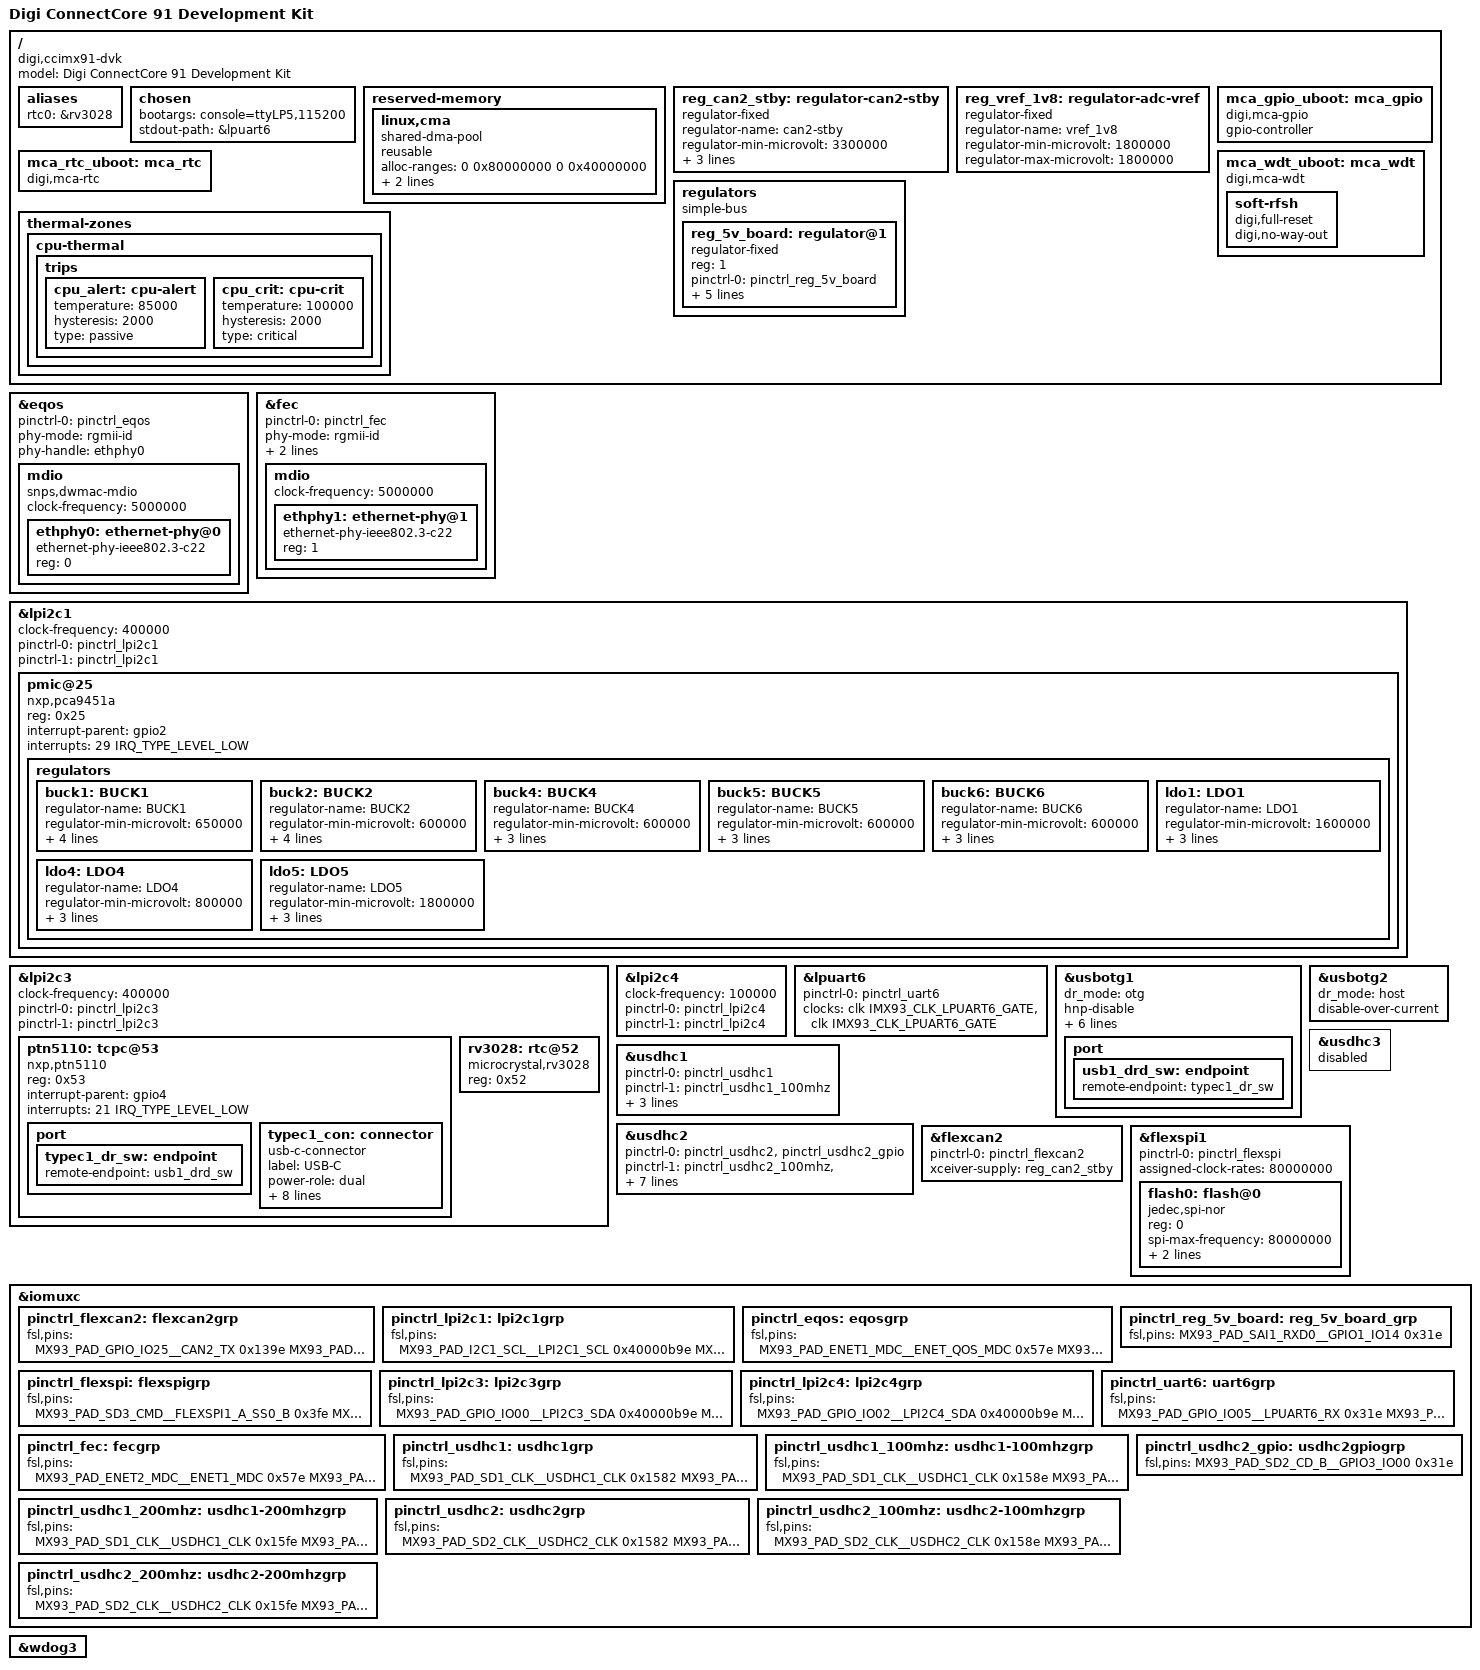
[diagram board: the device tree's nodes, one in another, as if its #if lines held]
// SPDX-License-Identifier: (GPL-2.0+ OR MIT)
/*
 * Copyright 2024 Digi International Inc
 */

/dts-v1/;

#include "imx93.dtsi"

/{
	model = "Digi ConnectCore 91 Development Kit";
	compatible = "digi,ccimx91-dvk", "digi,ccimx91", "fsl,imx91";

	aliases {
		rtc0 = &rv3028;
	};

	chosen {
		bootargs = "console=ttyLP5,115200";
		stdout-path = &lpuart6;
	};

	reserved-memory {
		#address-cells = <2>;
		#size-cells = <2>;
		ranges;

		linux,cma {
			compatible = "shared-dma-pool";
			reusable;
			alloc-ranges = <0 0x80000000 0 0x40000000>;
			size = <0 0x10000000>;
			linux,cma-default;
		};
	};

	reg_can2_stby: regulator-can2-stby {
		compatible = "regulator-fixed";
		regulator-name = "can2-stby";
		regulator-min-microvolt = <3300000>;
		regulator-max-microvolt = <3300000>;
		gpio = <&gpio1 13 GPIO_ACTIVE_LOW>;
		enable-active-low;
	};

	reg_vref_1v8: regulator-adc-vref {
		compatible = "regulator-fixed";
		regulator-name = "vref_1v8";
		regulator-min-microvolt = <1800000>;
		regulator-max-microvolt = <1800000>;
	};

	mca_gpio_uboot: mca_gpio {
		compatible = "digi,mca-gpio";
		gpio-controller;
	};

	mca_rtc_uboot: mca_rtc {
		compatible = "digi,mca-rtc";
	};

	mca_wdt_uboot: mca_wdt {
		compatible = "digi,mca-wdt";

		soft-rfsh {
			digi,full-reset;
			digi,no-way-out;
		};
	};

	regulators {
		compatible = "simple-bus";
		#address-cells = <1>;
		#size-cells = <0>;

		reg_5v_board: regulator@1 {
			compatible = "regulator-fixed";
			reg = <1>;
			pinctrl-names = "default";
			pinctrl-0 = <&pinctrl_reg_5v_board>;
			regulator-name = "5v_board";
			regulator-min-microvolt = <5000000>;
			regulator-max-microvolt = <5000000>;
			gpio = <&gpio1 14 GPIO_ACTIVE_HIGH>;
			enable-active-high;
		};
	};

	thermal-zones {
		cpu-thermal {
			trips {
				cpu_alert: cpu-alert {
					temperature = <85000>;
					hysteresis = <2000>;
					type = "passive";
				};

				cpu_crit: cpu-crit {
					temperature = <100000>;
					hysteresis = <2000>;
					type = "critical";
				};
			};
		};
	};
};

#if defined(CONFIG_DWC_ETH_QOS)
&eqos {
	pinctrl-names = "default";
	pinctrl-0 = <&pinctrl_eqos>;
	phy-mode = "rgmii-id";
	phy-handle = <&ethphy0>;
	status = "okay";

	mdio {
		compatible = "snps,dwmac-mdio";
		#address-cells = <1>;
		#size-cells = <0>;
		clock-frequency = <5000000>;

		ethphy0: ethernet-phy@0 {
			compatible = "ethernet-phy-ieee802.3-c22";
			reg = <0>;
		};
	};
};
#endif

#if defined(CONFIG_FEC_MXC)
&fec {
	pinctrl-names = "default";
	pinctrl-0 = <&pinctrl_fec>;
	phy-mode = "rgmii-id";
	phy-handle = <&ethphy1>;
	fsl,magic-packet;
	status = "okay";

	mdio {
		#address-cells = <1>;
		#size-cells = <0>;
		clock-frequency = <5000000>;

		ethphy1: ethernet-phy@1 {
			/* PHY ID for Marvell 88E1512 */
			compatible = "ethernet-phy-ieee802.3-c22";
			reg = <1>;
		};
	};
};
#endif

&lpi2c1 {
	#address-cells = <1>;
	#size-cells = <0>;
	clock-frequency = <400000>;
	pinctrl-names = "default", "sleep";
	pinctrl-0 = <&pinctrl_lpi2c1>;
	pinctrl-1 = <&pinctrl_lpi2c1>;
	status = "okay";

	pmic@25 {
		compatible = "nxp,pca9451a";
		reg = <0x25>;
		interrupt-parent = <&gpio2>;
		interrupts = <29 IRQ_TYPE_LEVEL_LOW>;

		regulators {
			buck1: BUCK1 {
				regulator-name = "BUCK1";
				regulator-min-microvolt = <650000>;
				regulator-max-microvolt = <2237500>;
				regulator-boot-on;
				regulator-always-on;
				regulator-ramp-delay = <3125>;
			};

			buck2: BUCK2 {
				regulator-name = "BUCK2";
				regulator-min-microvolt = <600000>;
				regulator-max-microvolt = <2187500>;
				regulator-boot-on;
				regulator-always-on;
				regulator-ramp-delay = <3125>;
			};

			buck4: BUCK4{
				regulator-name = "BUCK4";
				regulator-min-microvolt = <600000>;
				regulator-max-microvolt = <3400000>;
				regulator-boot-on;
				regulator-always-on;
			};

			buck5: BUCK5{
				regulator-name = "BUCK5";
				regulator-min-microvolt = <600000>;
				regulator-max-microvolt = <3400000>;
				regulator-boot-on;
				regulator-always-on;
			};

			buck6: BUCK6 {
				regulator-name = "BUCK6";
				regulator-min-microvolt = <600000>;
				regulator-max-microvolt = <3400000>;
				regulator-boot-on;
				regulator-always-on;
			};

			ldo1: LDO1 {
				regulator-name = "LDO1";
				regulator-min-microvolt = <1600000>;
				regulator-max-microvolt = <3300000>;
				regulator-boot-on;
				regulator-always-on;
			};

			ldo4: LDO4 {
				regulator-name = "LDO4";
				regulator-min-microvolt = <800000>;
				regulator-max-microvolt = <3300000>;
				regulator-boot-on;
				regulator-always-on;
			};

			ldo5: LDO5 {
				regulator-name = "LDO5";
				regulator-min-microvolt = <1800000>;
				regulator-max-microvolt = <3300000>;
				regulator-boot-on;
				regulator-always-on;
			};
		};
	};
};

&lpi2c3 {
	#address-cells = <1>;
	#size-cells = <0>;
	clock-frequency = <400000>;
	pinctrl-names = "default", "sleep";
	pinctrl-0 = <&pinctrl_lpi2c3>;
	pinctrl-1 = <&pinctrl_lpi2c3>;
	status = "okay";

	ptn5110: tcpc@53 {
		compatible = "nxp,ptn5110";
		reg = <0x53>;
		interrupt-parent = <&gpio4>;
		interrupts = <21 IRQ_TYPE_LEVEL_LOW>;
		status = "okay";

		port {
			typec1_dr_sw: endpoint {
				remote-endpoint = <&usb1_drd_sw>;
			};
		};

		typec1_con: connector {
			compatible = "usb-c-connector";
			label = "USB-C";
			power-role = "dual";
			data-role = "dual";
			try-power-role = "sink";
			source-pdos = <PDO_FIXED(5000, 3000, PDO_FIXED_USB_COMM)>;
			sink-pdos = <PDO_FIXED(5000, 3000, PDO_FIXED_USB_COMM)
				     PDO_VAR(5000, 20000, 3000)>;
			op-sink-microwatt = <15000000>;
			self-powered;
		};
	};

	rv3028: rtc@52 {
		compatible = "microcrystal,rv3028";
		reg = <0x52>;
	};
};

&lpi2c4 {
	#address-cells = <1>;
	#size-cells = <0>;
	clock-frequency = <100000>;
	pinctrl-names = "default", "sleep";
	pinctrl-0 = <&pinctrl_lpi2c4>;
	pinctrl-1 = <&pinctrl_lpi2c4>;
	status = "okay";
};

&lpuart6 { /* console */
	pinctrl-names = "default";
	pinctrl-0 = <&pinctrl_uart6>;
	clocks = <&clk IMX93_CLK_LPUART6_GATE>, <&clk IMX93_CLK_LPUART6_GATE>;
	clock-names = "ipg", "per";
	status = "okay";
};

/* USB_OTG1 - USB TypeC */
&usbotg1 {
	dr_mode = "otg";
	hnp-disable;
	srp-disable;
	adp-disable;
	usb-role-switch;
	disable-over-current;
	samsung,picophy-pre-emp-curr-control = <3>;
	samsung,picophy-dc-vol-level-adjust = <7>;
	status = "okay";

	port {
		usb1_drd_sw: endpoint {
			remote-endpoint = <&typec1_dr_sw>;
		};
	};
};

/* USB_OTG2 connected to usb hub */
&usbotg2 {
	dr_mode = "host";
	disable-over-current;
	status = "okay";
};

&usdhc1 {
	pinctrl-names = "default", "state_100mhz", "state_200mhz";
	pinctrl-0 = <&pinctrl_usdhc1>;
	pinctrl-1 = <&pinctrl_usdhc1_100mhz>;
	pinctrl-2 = <&pinctrl_usdhc1_200mhz>;
	bus-width = <8>;
	non-removable;
	status = "okay";
};

&usdhc2 {
	pinctrl-names = "default", "state_100mhz", "state_200mhz";
	pinctrl-0 = <&pinctrl_usdhc2>, <&pinctrl_usdhc2_gpio>;
	pinctrl-1 = <&pinctrl_usdhc2_100mhz>, <&pinctrl_usdhc2_gpio>;
	pinctrl-2 = <&pinctrl_usdhc2_200mhz>, <&pinctrl_usdhc2_gpio>;
	cd-gpios = <&gpio3 00 GPIO_ACTIVE_HIGH>;
	bus-width = <4>;
	status = "okay";
	no-sdio;
	no-mmc;
};

&usdhc3 {
	status = "disabled";
};

&flexcan2 {
	pinctrl-names = "default";
	pinctrl-0 = <&pinctrl_flexcan2>;
	xceiver-supply = <&reg_can2_stby>;
	status = "okay";
};

&flexspi1 {
	pinctrl-names = "default";
	pinctrl-0 = <&pinctrl_flexspi>;
	assigned-clock-rates = <80000000>;
	status = "okay";

	flash0: flash@0 {
		reg = <0>;
		#address-cells = <1>;
		#size-cells = <1>;
		compatible = "jedec,spi-nor";
		spi-max-frequency = <80000000>;
		spi-tx-bus-width = <4>;
		spi-rx-bus-width = <4>;
	};
};

&iomuxc {
	pinctrl_flexcan2: flexcan2grp {
		fsl,pins = <
			MX93_PAD_GPIO_IO25__CAN2_TX	0x139e
			MX93_PAD_GPIO_IO27__CAN2_RX	0x139e
		>;
	};

	pinctrl_lpi2c1: lpi2c1grp {
		fsl,pins = <
			MX93_PAD_I2C1_SCL__LPI2C1_SCL		0x40000b9e
			MX93_PAD_I2C1_SDA__LPI2C1_SDA		0x40000b9e
		>;
	};

	pinctrl_eqos: eqosgrp {
		fsl,pins = <
			MX93_PAD_ENET1_MDC__ENET_QOS_MDC			0x57e
			MX93_PAD_ENET1_MDIO__ENET_QOS_MDIO			0x57e
			MX93_PAD_ENET1_RD0__ENET_QOS_RGMII_RD0			0x57e
			MX93_PAD_ENET1_RD1__ENET_QOS_RGMII_RD1			0x57e
			MX93_PAD_ENET1_RD2__ENET_QOS_RGMII_RD2			0x57e
			MX93_PAD_ENET1_RD3__ENET_QOS_RGMII_RD3			0x57e
			MX93_PAD_ENET1_RXC__CCM_ENET_QOS_CLOCK_GENERATE_RX_CLK	0x5fe
			MX93_PAD_ENET1_RX_CTL__ENET_QOS_RGMII_RX_CTL		0x57e
			MX93_PAD_ENET1_TD0__ENET_QOS_RGMII_TD0			0x57e
			MX93_PAD_ENET1_TD1__ENET_QOS_RGMII_TD1			0x57e
			MX93_PAD_ENET1_TD2__ENET_QOS_RGMII_TD2			0x57e
			MX93_PAD_ENET1_TD3__ENET_QOS_RGMII_TD3			0x57e
			MX93_PAD_ENET1_TXC__CCM_ENET_QOS_CLOCK_GENERATE_TX_CLK	0x5fe
			MX93_PAD_ENET1_TX_CTL__ENET_QOS_RGMII_TX_CTL		0x57e
		>;
	};

	pinctrl_flexspi: flexspigrp {
		fsl,pins = <
			MX93_PAD_SD3_CMD__FLEXSPI1_A_SS0_B	0x3fe
			MX93_PAD_SD3_CLK__FLEXSPI1_A_SCLK	0x3fe
			MX93_PAD_SD3_DATA0__FLEXSPI1_A_DATA00	0x3fe
			MX93_PAD_SD3_DATA1__FLEXSPI1_A_DATA01	0x3fe
			MX93_PAD_SD3_DATA2__FLEXSPI1_A_DATA02	0x3fe
			MX93_PAD_SD3_DATA3__FLEXSPI1_A_DATA03	0x3fe
		>;
	};

	pinctrl_lpi2c3: lpi2c3grp {
		fsl,pins = <
			MX93_PAD_GPIO_IO00__LPI2C3_SDA		0x40000b9e
			MX93_PAD_GPIO_IO01__LPI2C3_SCL		0x40000b9e
		>;
	};

	pinctrl_lpi2c4: lpi2c4grp {
		fsl,pins = <
			MX93_PAD_GPIO_IO02__LPI2C4_SDA		0x40000b9e
			MX93_PAD_GPIO_IO03__LPI2C4_SCL		0x40000b9e
		>;
	};

	/* DVK 5V power switch */
	pinctrl_reg_5v_board: reg_5v_board_grp {
		fsl,pins = <
			/* 5V regulator power enable */
			MX93_PAD_SAI1_RXD0__GPIO1_IO14				0x31e
		>;
	};

	pinctrl_fec: fecgrp {
		fsl,pins = <
			MX93_PAD_ENET2_MDC__ENET1_MDC			0x57e
			MX93_PAD_ENET2_MDIO__ENET1_MDIO			0x57e
			MX93_PAD_ENET2_RD0__ENET1_RGMII_RD0		0x57e
			MX93_PAD_ENET2_RD1__ENET1_RGMII_RD1		0x57e
			MX93_PAD_ENET2_RD2__ENET1_RGMII_RD2		0x57e
			MX93_PAD_ENET2_RD3__ENET1_RGMII_RD3		0x57e
			MX93_PAD_ENET2_RXC__ENET1_RGMII_RXC		0x5fe
			MX93_PAD_ENET2_RX_CTL__ENET1_RGMII_RX_CTL	0x57e
			MX93_PAD_ENET2_TD0__ENET1_RGMII_TD0		0x57e
			MX93_PAD_ENET2_TD1__ENET1_RGMII_TD1		0x57e
			MX93_PAD_ENET2_TD2__ENET1_RGMII_TD2		0x57e
			MX93_PAD_ENET2_TD3__ENET1_RGMII_TD3		0x57e
			MX93_PAD_ENET2_TXC__ENET1_RGMII_TXC		0x5fe
			MX93_PAD_ENET2_TX_CTL__ENET1_RGMII_TX_CTL	0x57e
		>;
	};

	pinctrl_uart6: uart6grp {
		fsl,pins = <
			MX93_PAD_GPIO_IO05__LPUART6_RX		0x31e
			MX93_PAD_GPIO_IO04__LPUART6_TX		0x31e
		>;
	};

	/* need to config the SION for data and cmd pad, refer to ERR052021 */
	pinctrl_usdhc1: usdhc1grp {
		fsl,pins = <
			MX93_PAD_SD1_CLK__USDHC1_CLK		0x1582
			MX93_PAD_SD1_CMD__USDHC1_CMD		0x40001382
			MX93_PAD_SD1_DATA0__USDHC1_DATA0	0x40001382
			MX93_PAD_SD1_DATA1__USDHC1_DATA1	0x40001382
			MX93_PAD_SD1_DATA2__USDHC1_DATA2	0x40001382
			MX93_PAD_SD1_DATA3__USDHC1_DATA3	0x40001382
			MX93_PAD_SD1_DATA4__USDHC1_DATA4	0x40001382
			MX93_PAD_SD1_DATA5__USDHC1_DATA5	0x40001382
			MX93_PAD_SD1_DATA6__USDHC1_DATA6	0x40001382
			MX93_PAD_SD1_DATA7__USDHC1_DATA7	0x40001382
			MX93_PAD_SD1_STROBE__USDHC1_STROBE	0x1582
		>;
	};

	/* need to config the SION for data and cmd pad, refer to ERR052021 */
	pinctrl_usdhc1_100mhz: usdhc1-100mhzgrp {
		fsl,pins = <
			MX93_PAD_SD1_CLK__USDHC1_CLK		0x158e
			MX93_PAD_SD1_CMD__USDHC1_CMD		0x4000138e
			MX93_PAD_SD1_DATA0__USDHC1_DATA0	0x4000138e
			MX93_PAD_SD1_DATA1__USDHC1_DATA1	0x4000138e
			MX93_PAD_SD1_DATA2__USDHC1_DATA2	0x4000138e
			MX93_PAD_SD1_DATA3__USDHC1_DATA3	0x4000138e
			MX93_PAD_SD1_DATA4__USDHC1_DATA4	0x4000138e
			MX93_PAD_SD1_DATA5__USDHC1_DATA5	0x4000138e
			MX93_PAD_SD1_DATA6__USDHC1_DATA6	0x4000138e
			MX93_PAD_SD1_DATA7__USDHC1_DATA7	0x4000138e
			MX93_PAD_SD1_STROBE__USDHC1_STROBE	0x158e
		>;
	};

	/* need to config the SION for data and cmd pad, refer to ERR052021 */
	pinctrl_usdhc1_200mhz: usdhc1-200mhzgrp {
		fsl,pins = <
			MX93_PAD_SD1_CLK__USDHC1_CLK		0x15fe
			MX93_PAD_SD1_CMD__USDHC1_CMD		0x400013fe
			MX93_PAD_SD1_DATA0__USDHC1_DATA0	0x400013fe
			MX93_PAD_SD1_DATA1__USDHC1_DATA1	0x400013fe
			MX93_PAD_SD1_DATA2__USDHC1_DATA2	0x400013fe
			MX93_PAD_SD1_DATA3__USDHC1_DATA3	0x400013fe
			MX93_PAD_SD1_DATA4__USDHC1_DATA4	0x400013fe
			MX93_PAD_SD1_DATA5__USDHC1_DATA5	0x400013fe
			MX93_PAD_SD1_DATA6__USDHC1_DATA6	0x400013fe
			MX93_PAD_SD1_DATA7__USDHC1_DATA7	0x400013fe
			MX93_PAD_SD1_STROBE__USDHC1_STROBE	0x15fe
		>;
	};

	pinctrl_usdhc2_gpio: usdhc2gpiogrp {
		fsl,pins = <
			MX93_PAD_SD2_CD_B__GPIO3_IO00		0x31e
		>;
	};

	/* need to config the SION for data and cmd pad, refer to ERR052021 */
	pinctrl_usdhc2: usdhc2grp {
		fsl,pins = <
			MX93_PAD_SD2_CLK__USDHC2_CLK		0x1582
			MX93_PAD_SD2_CMD__USDHC2_CMD		0x40001382
			MX93_PAD_SD2_DATA0__USDHC2_DATA0	0x40001382
			MX93_PAD_SD2_DATA1__USDHC2_DATA1	0x40001382
			MX93_PAD_SD2_DATA2__USDHC2_DATA2	0x40001382
			MX93_PAD_SD2_DATA3__USDHC2_DATA3	0x40001382
			MX93_PAD_SD2_VSELECT__USDHC2_VSELECT	0x51e
		>;
	};

	/* need to config the SION for data and cmd pad, refer to ERR052021 */
	pinctrl_usdhc2_100mhz: usdhc2-100mhzgrp {
		fsl,pins = <
			MX93_PAD_SD2_CLK__USDHC2_CLK		0x158e
			MX93_PAD_SD2_CMD__USDHC2_CMD		0x4000138e
			MX93_PAD_SD2_DATA0__USDHC2_DATA0	0x4000138e
			MX93_PAD_SD2_DATA1__USDHC2_DATA1	0x4000138e
			MX93_PAD_SD2_DATA2__USDHC2_DATA2	0x4000138e
			MX93_PAD_SD2_DATA3__USDHC2_DATA3	0x4000138e
			MX93_PAD_SD2_VSELECT__USDHC2_VSELECT	0x51e
		>;
	};

	/* need to config the SION for data and cmd pad, refer to ERR052021 */
	pinctrl_usdhc2_200mhz: usdhc2-200mhzgrp {
		fsl,pins = <
			MX93_PAD_SD2_CLK__USDHC2_CLK		0x15fe
			MX93_PAD_SD2_CMD__USDHC2_CMD		0x400013fe
			MX93_PAD_SD2_DATA0__USDHC2_DATA0	0x400013fe
			MX93_PAD_SD2_DATA1__USDHC2_DATA1	0x400013fe
			MX93_PAD_SD2_DATA2__USDHC2_DATA2	0x400013fe
			MX93_PAD_SD2_DATA3__USDHC2_DATA3	0x400013fe
			MX93_PAD_SD2_VSELECT__USDHC2_VSELECT	0x51e
		>;
	};
};

&wdog3 {
	status = "okay";
};
